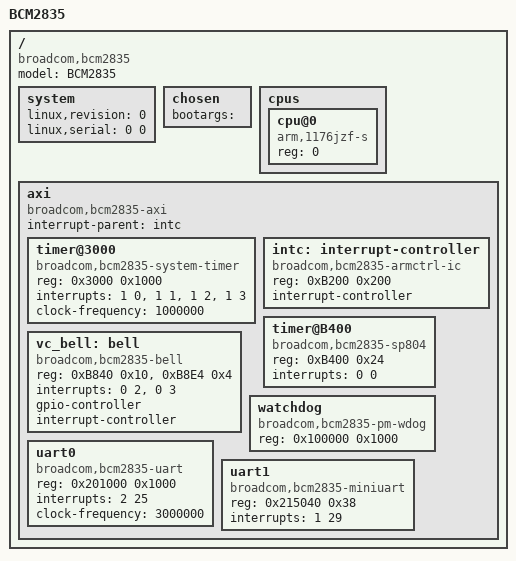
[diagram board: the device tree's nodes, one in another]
/include/ "skeleton.dtsi"

/ {
	model = "BCM2835";
	compatible = "broadcom,bcm2835", "broadcom,bcm2708";

	system {
		linux,revision = <0>;		/* Set by VideoCore */
		linux,serial = <0 0>;		/* Set by VideoCore */
	};

	chosen {
		bootargs = "";			/* Set by VideoCore */
	};

	cpus {
		#address-cells = <1>;
		#size-cells = <0>;

		cpu@0 {
			compatible = "arm,1176jzf-s";
			reg = <0>;
		};
	};

	axi {
		compatible = "broadcom,bcm2835-axi", "broadcom,bcm2708-axi", "simple-bus";
		#address-cells = <1>;
		#size-cells = <1>;
		ranges = <0 0x20000000 0x01000000>;
		interrupt-parent = <&intc>;

		timer@3000 {
			compatible = "broadcom,bcm2835-system-timer", "broadcom,bcm2708-system-timer";
			reg = <0x3000 0x1000>;
			interrupts = <1 0>, <1 1>, <1 2>, <1 3>;

			clock-frequency = <1000000>;
		};

		intc: interrupt-controller {
			compatible = "broadcom,bcm2835-armctrl-ic", "broadcom,bcm2708-armctrl-ic";
			reg = <0xB200 0x200>;

			interrupt-controller;
			#interrupt-cells = <2>;

			/* Bank 0
			 * 0: ARM_TIMER
			 * 1: ARM_MAILBOX
			 * 2: ARM_DOORBELL_0
			 * 3: ARM_DOORBELL_1
			 * 4: VPU0_HALTED
			 * 5: VPU1_HALTED
			 * 6: ILLEGAL_TYPE0
			 * 7: ILLEGAL_TYPE1
			 */

			/* Bank 1
			 * 0: TIMER0		16: DMA0
			 * 1: TIMER1		17: DMA1
			 * 2: TIMER2		18: VC_DMA2
			 * 3: TIMER3		19: VC_DMA3
			 * 4: CODEC0		20: DMA4
			 * 5: CODEC1		21: DMA5
			 * 6: CODEC2		22: DMA6
			 * 7: VC_JPEG		23: DMA7
			 * 8: ISP		24: DMA8
			 * 9: VC_USB		25: DMA9
			 * 10: VC_3D		26: DMA10
			 * 11: TRANSPOSER	27: DMA11
			 * 12: MULTICORESYNC0	28: DMA12
			 * 13: MULTICORESYNC1	29: AUX
			 * 14: MULTICORESYNC2	30: ARM
			 * 15: MULTICORESYNC3	31: VPUDMA
			 */

			/* Bank 2
			 * 0: HOSTPORT		16: SMI
			 * 1: VIDEOSCALER	17: GPIO0
			 * 2: CCP2TX		18: GPIO1
			 * 3: SDC		19: GPIO2
			 * 4: DSI0		20: GPIO3
			 * 5: AVE		21: VC_I2C
			 * 6: CAM0		22: VC_SPI
			 * 7: CAM1		23: VC_I2SPCM
			 * 8: HDMI0		24: VC_SDIO
			 * 9: HDMI1		25: VC_UART
			 * 10: PIXELVALVE1	26: SLIMBUS
			 * 11: I2CSPISLV	27: VEC
			 * 12: DSI1		28: CPG
			 * 13: PWA0		29: RNG
			 * 14: PWA1		30: VC_ARASANSDIO
			 * 15: CPR		31: AVSPMON
			 */
		};

		timer@B400 {
			/* Not AMBA compatible */
			compatible = "broadcom,bcm2835-sp804", "broadcom,bcm2708-sp804", "arm,sp804";
			reg = <0xB400 0x24>;
			interrupts = <0 0>;
		};

		vc_bell: bell {
			compatible = "broadcom,bcm2835-bell", "broadcom,bcm2708-bell";
			reg = <0xB840 0x10>, <0xB8E4 0x4>;
			interrupts = <0 2>, <0 3>;

			gpio-controller;
			#gpio-cells = <1>;

			interrupt-controller;
			#interrupt-cells = <1>;
		};

		watchdog {
			compatible = "broadcom,bcm2835-pm-wdog", "broadcom,bcm2708-pm-wdog";
			reg = <0x100000 0x1000>;
		};

		uart0 {
			compatible = "broadcom,bcm2835-uart", "broadcom,bcm2708-uart", "arm,pl011", "arm,primecell";
			reg = <0x201000 0x1000>;
			interrupts = <2 25>;

			clock-frequency = <3000000>;	/* Set by VideoCore */
		};

		uart1 {
			compatible = "broadcom,bcm2835-miniuart", "broadcom,bcm2708-miniuart", "ns16550";
			reg = <0x215040 0x38>;
			interrupts = <1 29>;
		};
	};
};
